# MMU1_Camera_MMU register map
Vendor: Texas Instruments
Peripheral module from a debugger description file (folder omap34xx).
Registers are 32-bit, access per field, reset 0x0 unless marked. A register's access mark holds for its fields unless they carry their own. Offsets are as the file gives them; lines under a group give offsets from that group; [hi:lo] are bit positions; {n}, {i} and the like mark numbered series; 'fields as' and 'values as' point back to an identical list; <NAME> marks a mode.

## MMU1_(Camera_MMU)
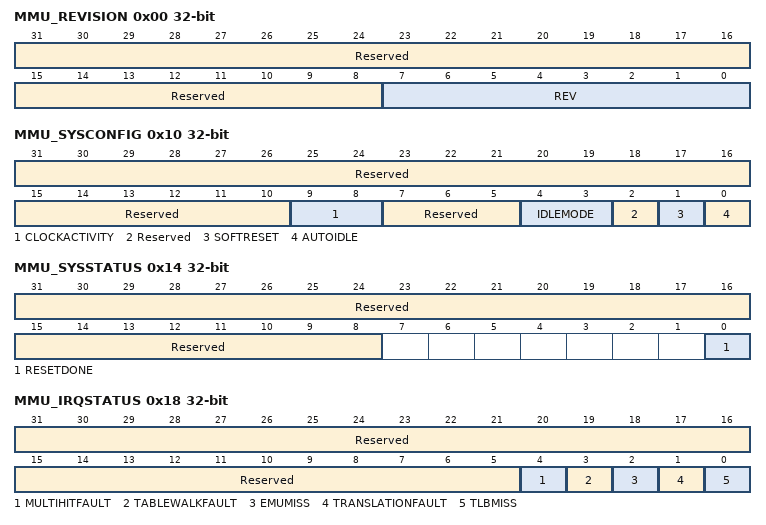
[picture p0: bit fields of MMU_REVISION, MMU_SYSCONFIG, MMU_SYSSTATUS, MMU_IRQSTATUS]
0x00 MMU_REVISION ro (reset mask 0xFFFFFF00) — This register contains the IP revision code.
  [31:8] Reserved — Reads return 0.
  [7:0] REV — IP revision[7:4]: Major revision [3:0]: Minor revision Examples: 0x10 for 1.0, 0x21 for 2.1
0x10 MMU_SYSCONFIG — This register contains the various parameters of the interconnect interface.
  [31:10] Reserved ro — Reads return 0. Write 0s for future compatibility.
  [9:8] CLOCKACTIVITY ro — Clock activity during wake-up modeRead 0x0: Functional and interconnect clocks can be switched off. Read 0x1, 0x2, 0x3: never happens. Write 0s for future compatibility.
  [7:5] Reserved ro — Reads return 0. Write 0s for future compatibility.
  [4:3] IDLEMODE rw
    0=Force idle. Idle request is acknowledged unconditionally.; 1=No idle. Idle request is never acknowledged.; 2=Smart idle. Acknowledgement to an idle request is given based on the internal activity of the module.; 3=Reserved - Do not use
  [2] Reserved ro — Reads return 0. Write 0s for future compatibility.
  [1] SOFTRESET rw — Software reset. This bit is automatically reset by the hardware. During reads, it always returns 0.
    0=SOFTRESET_0_r (Always returns 0); 0=SOFTRESET_0_w (No functional effect); 1=SOFTRESET_1_r (Never happens); 1=SOFTRESET_1_w (The module is reset.)
  [0] AUTOIDLE rw — Internal interconnect clock gating strategy
    0=Interconnect clock is free-running; 1=Automatic interconnect clock gating strategy is applied, based on the interconnect interface activity
0x14 MMU_SYSSTATUS ro (reset mask 0xFFFFFFFE) — This register provides status information about the module, excluding the interrupt status information.
  [31:8] Reserved — Reads return 0.
  [0] RESETDONE — Internal reset monitoring
    0=Internal module reset in ongoing; 1=Reset completed
0x18 MMU_IRQSTATUS — This interrupt status register regroups all the status of the module internal events that can generate an interrupt.
  [31:5] Reserved ro — Reads return 0. Write 0s for future compatibility.
  [4] MULTIHITFAULT rw — Error due to multiple matches in the TLB
    0=MULTIHITFAULT_0_r (MultiHitFault false); 0=MULTIHITFAULT_0_w (MultiHitFault status bit unchanged); 1=MULTIHITFAULT_1_r (MultiHitFault is true (pending)); 1=MULTIHITFAULT_1_w (TableWalkFault status bit is reset)
  [3] TABLEWALKFAULT rw — Error response received during a table walk
    0=TABLEWALKFAULT_0_r (TableWalkFault false); 0=TABLEWALKFAULT_0_w (TableWalkFault status bit unchanged); 1=TABLEWALKFAULT_1_r (TableWalkFault is true (pending)); 1=TABLEWALKFAULT_1_w (TableWalkFault status bit is reset)
  [2] EMUMISS rw — Unrecoverable TLB miss during debug (hardware TWL disabled)
    0=EMUMISS_0_r (EMUMiss false); 0=EMUMISS_0_w (EMUMiss status bit unchanged); 1=EMUMISS_1_r (EMUMiss is true (pending)); 1=EMUMISS_1_w (EMUMiss status bit is reset)
  [1] TRANSLATIONFAULT rw — Invalid descriptor in translation tables (translation fault)
    0=TRANSLATIONFAULT_0_r (TranslationFault false); 0=TRANSLATIONFAULT_0_w (TranslationFault status bit unchanged); 1=TRANSLATIONFAULT_1_r (TranslationFault is true (pending)); 1=TRANSLATIONFAULT_1_w (TranslationFault status bit is reset)
  [0] TLBMISS rw — Unrecoverable TLB miss (hardware TWL disabled)
    0=TLBMISS_0_r (TLBMiss false); 0=TLBMISS_0_w (TLBMiss status bit unchanged); 1=TLBMISS_1_r (TLBMiss is true (pending)); 1=TLBMISS_1_w (TLBMiss status bit is reset)
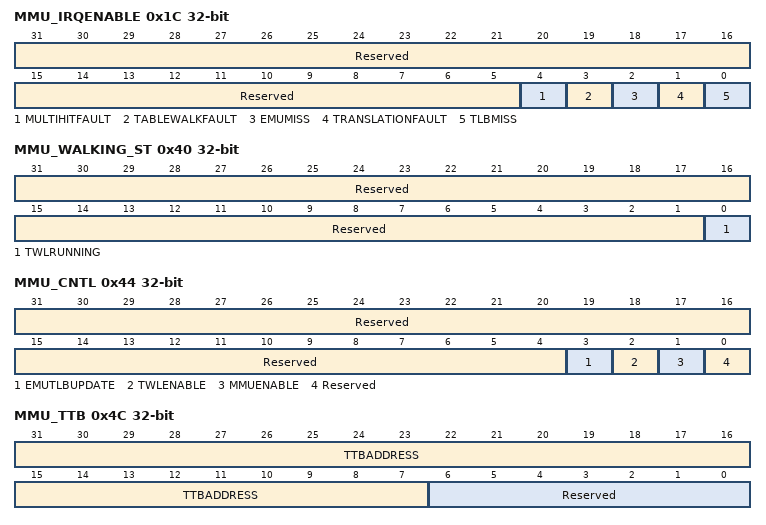
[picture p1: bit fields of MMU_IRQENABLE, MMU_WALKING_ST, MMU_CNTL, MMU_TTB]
0x1C MMU_IRQENABLE — The interrupt enable register allows the module's internal sources of interrupt to be masked and unmasked on an event-by-event basis..
  [31:5] Reserved ro — Reads return 0. Write 0s for future compatibility.
  [4] MULTIHITFAULT rw — Error due to multiple matches in the TLB
    0=MultiHitFault interrupt is masked; 1=MultiHitFault event generates an interrupt if occurs
  [3] TABLEWALKFAULT rw — Error response received during a table walk
    0=TableWalkFault interrupt is masked; 0=TableWalkFault event generates an interrupt if occurs
  [2] EMUMISS rw — Unrecoverable TLB miss during debug (hardware TWL disabled)
    0=EMUMiss interrupt is masked; 1=EMUMiss event generates an interrupt if occurs
  [1] TRANSLATIONFAULT rw — Invalid descriptor in translation tables (translation fault)
    0=TranslationFault interrupt is masked; 1=TranslationFault generates an interrupt if occurs
  [0] TLBMISS rw — Unrecoverable TLB miss (hardware TWL disabled)
    0=TLBMiss interrupt is masked; 1=TLBMiss event generates an interrupt if occurs
0x40 MMU_WALKING_ST ro — This register provides status information about the table walking logic.
  [31:1] Reserved — Reads return 0.
  [0] TWLRUNNING — Table walking logic is running.
    0=TWL completed; 1=TWL running
0x44 MMU_CNTL — This register programs the MMU features.
  [31:4] Reserved ro — Reads return 0. Write 0s for future compatibility.
  [3] EMUTLBUPDATE rw — Enable TLB update on emulator table walk
    0=Emulator TLB update disabled; 1=Emulator TLB update enabled
  [2] TWLENABLE rw — Table walking logic enable
    0=TWL disabled; 0=TWL enabled
  [1] MMUENABLE rw
    0=MMU disabled; 1=MMU enabled
  [0] Reserved ro — Reads return 0. Write 0s for future compatibility.
0x48 MMU_FAULT_AD ro — This register contains the virtual address that generated the interrupt.
  [31:0] FAULTADDRESS — Virtual address of the access that generated a fault
0x4C MMU_TTB — This register contains the resolution table base address.
  [31:7] TTBADDRESS rw — Translation table base address
  [6:0] Reserved ro — Reads return 0. Write 0s for future compatibility.
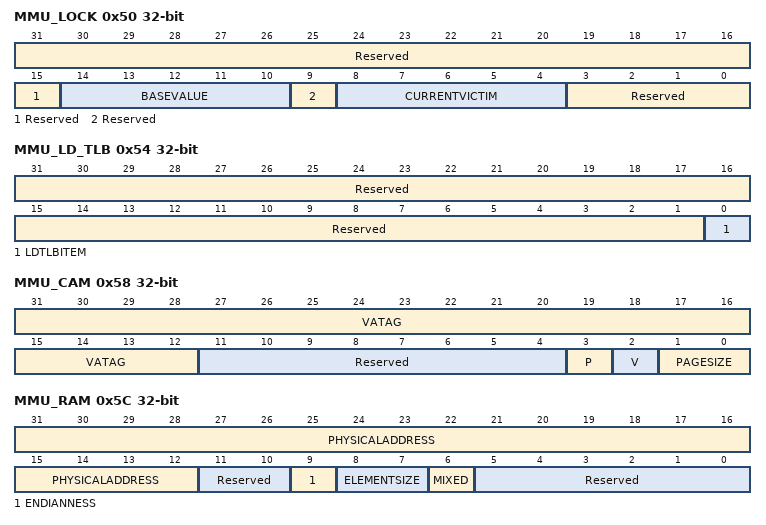
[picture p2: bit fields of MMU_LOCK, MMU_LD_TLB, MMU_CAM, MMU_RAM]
0x50 MMU_LOCK — This register locks some of the TLB entries or specifies the TLB entry to be read.
  [31:15] Reserved ro — Reads return 0. Write 0s for future compatibility.
  [14:10] BASEVALUE rw — Locked entries base valueNote: In the Camera MMU instance, BASEVALUE is a 3-bit field, ie. bits 13 and 14 are reserved.
  [9] Reserved ro — Reads return 0. Write 0s for future compatibility.
  [8:4] CURRENTVICTIM rw — Current entry to be updated either by the TWL or by the software or TLB entry to be readNote: In the Camera MMU instance, CURRENTVICTIM is a 3-bit field, ie. bits 7 and 8 are reserved.Write value: TLB entry to be updated by software or TLB entry to be readRead value: TLB entry to be updated by table walk logic
  [3:0] Reserved ro — Reads return 0. Write 0s for future compatibility.
0x54 MMU_LD_TLB — This register loads a TLB entry (CAM+RAM).
  [31:1] Reserved ro — Reads return 0. Write 0s for future compatibility
  [0] LDTLBITEM rw — Write (load) data in the TLB
    0=LDTLBITEM_0_r (Always returns 0); 0=LDTLBITEM_0_w (No functional effect); 1=LDTLBITEM_1_r (Never happens); 1=LDTLBITEM_1_w (Load TLB data)
0x58 MMU_CAM — This register holds a CAM entry.
  [31:12] VATAG rw — Virtual address tag
  [11:4] Reserved ro — Reads return 0. Write 0s for future compatibility.
  [3] P rw — Preserved bit
    0=TLB entry can be flushed; 1=TLB entry is protected against flush
  [2] V rw — Valid bit
    0=TLB entry is invalid; 1=TLB entry is valid
  [1:0] PAGESIZE rw
    0=Section (1MB); 1=Large page (64KB); 2=Small page (4KB); 3=Supersection (16MB)
0x5C MMU_RAM — This register holds a RAM entry.
  [31:12] PHYSICALADDRESS rw — Physical address of the page
  [11:10] Reserved ro — Reads return 0. Write 0s for future compatibility.
  [9] ENDIANNESS rw — Endianness of the page
    0=Little endian; 1=Big endian -must not be used (locked on little endian)
  [8:7] ELEMENTSIZE rw — Element size of the page (8, 16, 32, no translation)
    0=8 bits; 1=16 bits; 2=32 bits; 3=No translation
  [6] MIXED rw — Mixed page attribute (use CPU element size)
    0=Use TLB element size; 1=Use CPU element size
  [5:0] Reserved ro — Reads return 0. Write 0s for future compatibility.
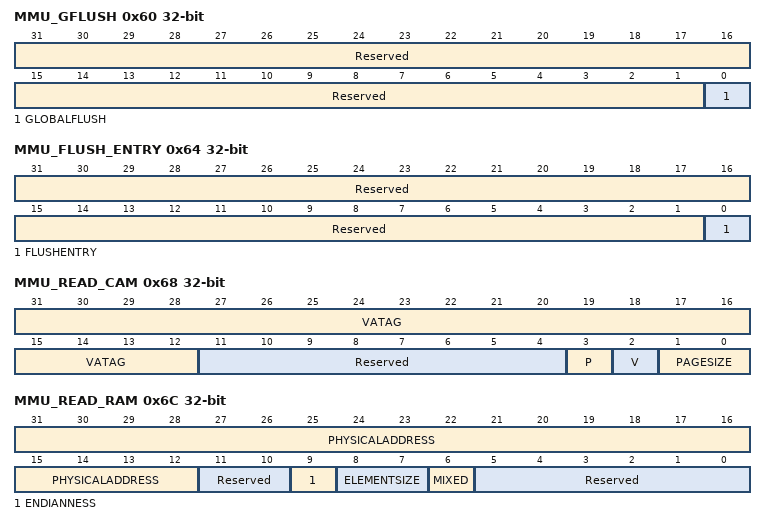
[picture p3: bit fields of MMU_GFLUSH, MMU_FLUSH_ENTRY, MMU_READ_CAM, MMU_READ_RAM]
0x60 MMU_GFLUSH rw — This register flushes all the non-protected TLB entries.
  [31:1] Reserved — Reads return 0. Write 0s for future compatibility.
  [0] GLOBALFLUSH — Flush all the non-protected TLB entries when set
    0=GLOBALFLUSH_0_r (Always returns 0); 0=GLOBALFLUSH_0_w (No functional effect); 1=GLOBALFLUSH_1_r (Never happens); 1=GLOBALFLUSH_1_w (Flush all the non-protected TLB entries)
0x64 MMU_FLUSH_ENTRY rw — This register flushes the entry pointed to by the CAM virtual address.
  [31:1] Reserved — Reads return 0. Write 0s for future compatibility.
  [0] FLUSHENTRY — Flush the TLB entry pointed by the virtual address (VATag) inMMU_CAM register, even if this entry is set protected
    0=FLUSHENTRY_0_r (Always returns 0); 0=FLUSHENTRY_0_w (No functional effect); 1=FLUSHENTRY_1_r (Never happens); 1=FLUSHENTRY_1_w (Flush all the TLB entries specified by the CAM register)
0x68 MMU_READ_CAM ro — This register reads CAM data from a CAM entry.
  [31:12] VATAG — Virtual address tag
  [11:4] Reserved — Reads return 0.
  [3] P — Preserved bit
    values as MMU_CAM.P
  [2] V — Valid bit
    0=TLB entry is invalid; 1=TLB entry is valid
  [1:0] PAGESIZE
    values as MMU_CAM.PAGESIZE
0x6C MMU_READ_RAM ro — This register reads RAM data from a RAM entry.
  [31:12] PHYSICALADDRESS — Physical address of the page
  [11:10] Reserved — Reads return 0.
  [9] ENDIANNESS — Endianness of the page
    values as MMU_RAM.ENDIANNESS
  [8:7] ELEMENTSIZE — Element size of the page (8, 16, 32 bits or no translation)
    0=8 bits; 1=16 bits; 2=32 bits; 3=No translation
  [6] MIXED — Mixed page attribute (use CPU element size)
    0=Use TLB element size; 1=Use CPU element size
  [5:0] Reserved — Reads return 0. Write 0s for future compatibility.
0x70 MMU_EMU_FAULT_AD ro — This register contains the last virtual address of a fault caused by the debugger.
  [31:0] EMUFAULTADDRESS — Virtual address of the last emulator access that generated a fault
